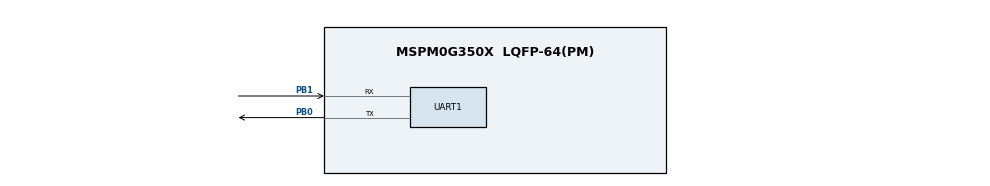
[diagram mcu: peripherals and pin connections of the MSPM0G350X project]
/**
 * @cliArgs --device "MSPM0G350X" --package "LQFP-64(PM)" --part "Default" --product "mspm0_sdk@2.01.00.03"
 * @versions {"tool":"1.20.0+3587"}
 */

/**
 * Import the modules used in this configuration.
 */
const ADC12         = scripting.addModule("/ti/driverlib/ADC12", {}, false);
const ADC121        = ADC12.addInstance();
const ADC122        = ADC12.addInstance();
const SYSCTL        = scripting.addModule("/ti/driverlib/SYSCTL");
const TIMER         = scripting.addModule("/ti/driverlib/TIMER", {}, false);
const TIMER1        = TIMER.addInstance();
const UART          = scripting.addModule("/ti/driverlib/UART", {}, false);
const UART1         = UART.addInstance();
const ProjectConfig = scripting.addModule("/ti/project_config/ProjectConfig");

/**
 * Write custom configuration values to the imported modules.
 */
const divider6       = system.clockTree["PLL_CLK2X_DIV"];
divider6.divideValue = 4;

const divider7       = system.clockTree["PLL_PDIV"];
divider7.divideValue = 2;

const divider9       = system.clockTree["UDIV"];
divider9.divideValue = 2;

const multiplier2         = system.clockTree["PLL_QDIV"];
multiplier2.multiplyValue = 10;

const mux8       = system.clockTree["HSCLKMUX"];
mux8.inputSelect = "HSCLKMUX_SYSPLL2X";

ADC121.$name                             = "ADC12_1";
ADC121.repeatMode                        = true;
ADC121.trigSrc                           = "DL_ADC12_TRIG_SRC_EVENT";
ADC121.adcMem0trig                       = "DL_ADC12_TRIGGER_MODE_TRIGGER_NEXT";
ADC121.powerDownMode                     = "DL_ADC12_POWER_DOWN_MODE_MANUAL";
ADC121.sampleTime0                       = "62.5ns";
ADC121.enabledInterrupts                 = ["DL_ADC12_INTERRUPT_DMA_DONE"];
ADC121.subChanID                         = 2;
ADC121.configureDMA                      = true;
ADC121.enableFIFO                        = true;
ADC121.sampCnt                           = 6;
ADC121.enabledDMATriggers                = ["DL_ADC12_DMA_MEM10_RESULT_LOADED"];
ADC121.interruptPriority                 = "0";
ADC121.adcMem0chansel                    = "DL_ADC12_INPUT_CHAN_5";
ADC121.peripheral.$assign                = "ADC1";
ADC121.peripheral.adcPin5.$assign        = "PB18";
ADC121.DMA_CHANNEL.$name                 = "DMA_CH1";
ADC121.DMA_CHANNEL.addressMode           = "f2b";
ADC121.DMA_CHANNEL.configureTransferSize = true;
ADC121.DMA_CHANNEL.transferSize          = 512;
ADC121.DMA_CHANNEL.transferMode          = "FULL_CH_REPEAT_SINGLE";
ADC121.adcPin5Config.$name               = "ti_driverlib_gpio_GPIOPinGeneric3";

ADC122.$name                             = "ADC12_0";
ADC122.repeatMode                        = true;
ADC122.trigSrc                           = "DL_ADC12_TRIG_SRC_EVENT";
ADC122.adcMem0trig                       = "DL_ADC12_TRIGGER_MODE_TRIGGER_NEXT";
ADC122.enableFIFO                        = true;
ADC122.powerDownMode                     = "DL_ADC12_POWER_DOWN_MODE_MANUAL";
ADC122.enabledInterrupts                 = ["DL_ADC12_INTERRUPT_DMA_DONE"];
ADC122.configureDMA                      = true;
ADC122.sampCnt                           = 6;
ADC122.enabledDMATriggers                = ["DL_ADC12_DMA_MEM10_RESULT_LOADED"];
ADC122.subChanID                         = 1;
ADC122.sampleTime0                       = "50us";
ADC122.peripheral.$assign                = "ADC0";
ADC122.peripheral.adcPin0.$assign        = "PA27";
ADC122.adcPin0Config.hideOutputInversion = scripting.forceWrite(false);
ADC122.adcPin0Config.$name               = "ti_driverlib_gpio_GPIOPinGeneric0";
ADC122.DMA_CHANNEL.$name                 = "DMA_CH0";
ADC122.DMA_CHANNEL.addressMode           = "f2b";
ADC122.DMA_CHANNEL.transferMode          = "FULL_CH_REPEAT_SINGLE";
ADC122.DMA_CHANNEL.configureTransferSize = true;
ADC122.DMA_CHANNEL.transferSize          = 512;

const Board = scripting.addModule("/ti/driverlib/Board", {}, false);

SYSCTL.forceDefaultClkConfig = true;
SYSCTL.clockTreeEn           = true;

TIMER1.$name                       = "TIMER_0";
TIMER1.timerMode                   = "PERIODIC";
TIMER1.event1PublisherChannel      = 1;
TIMER1.event1ControllerInterruptEn = ["ZERO_EVENT"];
TIMER1.timerPeriod                 = "97656ns";
TIMER1.event2ControllerInterruptEn = ["ZERO_EVENT"];
TIMER1.event2PublisherChannel      = 2;
TIMER1.peripheral.$assign          = "TIMG0";

UART1.$name                    = "UART_0";
UART1.targetBaudRate           = 115200;
UART1.enabledInterrupts        = ["RX"];
UART1.peripheral.$assign       = "UART0";
UART1.peripheral.rxPin.$assign = "PB1";
UART1.peripheral.txPin.$assign = "PB0";
UART1.txPinConfig.$name        = "ti_driverlib_gpio_GPIOPinGeneric1";
UART1.rxPinConfig.$name        = "ti_driverlib_gpio_GPIOPinGeneric2";

ProjectConfig.genLibCMSIS = true;

/**
 * Pinmux solution for unlocked pins/peripherals. This ensures that minor changes to the automatic solver in a future
 * version of the tool will not impact the pinmux you originally saw.  These lines can be completely deleted in order to
 * re-solve from scratch.
 */
ADC121.DMA_CHANNEL.peripheral.$suggestSolution = "DMA_CH1";
ADC122.DMA_CHANNEL.peripheral.$suggestSolution = "DMA_CH0";
Board.peripheral.$suggestSolution              = "DEBUGSS";
Board.peripheral.swclkPin.$suggestSolution     = "PA20";
Board.peripheral.swdioPin.$suggestSolution     = "PA19";
